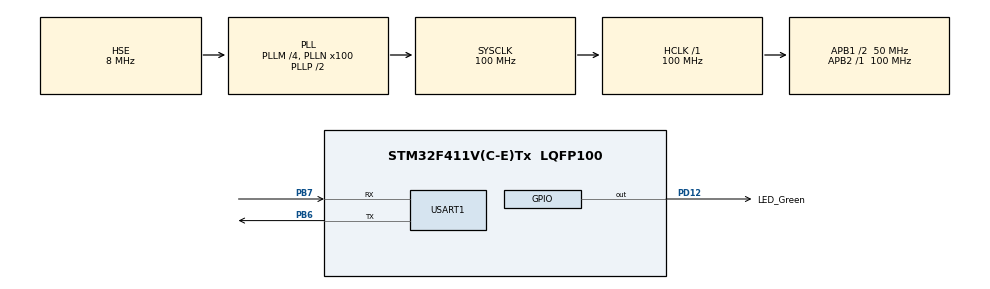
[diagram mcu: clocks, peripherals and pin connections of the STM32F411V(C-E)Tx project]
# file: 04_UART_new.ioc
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Dma.Request0=USART1_RX
Dma.Request1=USART1_TX
Dma.USART1_RX.0.Direction=DMA_PERIPH_TO_MEMORY
Dma.USART1_RX.0.FIFOMode=DMA_FIFOMODE_DISABLE
Dma.USART1_RX.0.Instance=DMA2_Stream2
Dma.USART1_RX.0.MemDataAlignment=DMA_MDATAALIGN_BYTE
Dma.USART1_RX.0.MemInc=DMA_MINC_ENABLE
Dma.USART1_RX.0.Mode=DMA_NORMAL
Dma.USART1_RX.0.PeriphDataAlignment=DMA_PDATAALIGN_BYTE
Dma.USART1_RX.0.PeriphInc=DMA_PINC_DISABLE
Dma.USART1_RX.0.Priority=DMA_PRIORITY_LOW
Dma.USART1_TX.1.Direction=DMA_MEMORY_TO_PERIPH
Dma.USART1_TX.1.FIFOMode=DMA_FIFOMODE_DISABLE
Dma.USART1_TX.1.Instance=DMA2_Stream7
Dma.USART1_TX.1.MemDataAlignment=DMA_MDATAALIGN_BYTE
Dma.USART1_TX.1.MemInc=DMA_MINC_ENABLE
Dma.USART1_TX.1.Mode=DMA_NORMAL
Dma.USART1_TX.1.PeriphDataAlignment=DMA_PDATAALIGN_BYTE
Dma.USART1_TX.1.PeriphInc=DMA_PINC_DISABLE
Dma.USART1_TX.1.Priority=DMA_PRIORITY_LOW
Mcu.Family=STM32F4
Mcu.Name=STM32F411V(C-E)Tx
Mcu.Package=LQFP100
NVIC.DMA2_Stream2_IRQn=true\:0\:0\:false\:false\:true
NVIC.DMA2_Stream7_IRQn=true\:0\:0\:false\:false\:true
NVIC.PriorityGroup=NVIC_PRIORITYGROUP_4
NVIC.TIM1_UP_TIM10_IRQn=true\:0\:0\:false\:false\:true
NVIC.USART1_IRQn=true\:0\:0\:false\:false\:true
PB6.Mode=Asynchronous
PB6.Signal=USART1_TX
PB7.Mode=Asynchronous
PB7.Signal=USART1_RX
PD12.GPIO_Label=LED_Green
PD12.Signal=GPIO_Output
PH0\ -\ OSC_IN.Mode=HSE-External-Oscillator
PH0\ -\ OSC_IN.Signal=RCC_OSC_IN
PH1\ -\ OSC_OUT.Mode=HSE-External-Oscillator
PH1\ -\ OSC_OUT.Signal=RCC_OSC_OUT
ProjectManager.HeapSize=0x200
ProjectManager.StackSize=0x400
ProjectManager.TargetToolchain=SW4STM32
RCC.48MHZClocksFreq_Value=50000000
RCC.AHBFreq_Value=100000000
RCC.APB1CLKDivider=RCC_HCLK_DIV2
RCC.APB1Freq_Value=50000000
RCC.APB1TimFreq_Value=100000000
RCC.APB2Freq_Value=100000000
RCC.APB2TimFreq_Value=100000000
RCC.CortexFreq_Value=100000000
RCC.HCLKFreq_Value=100000000
RCC.HSE_VALUE=8000000
RCC.HSI_VALUE=16000000
RCC.LSE_VALUE=32768
RCC.PLLM=4
RCC.PLLN=100
RCC.PLLSourceVirtual=RCC_PLLSOURCE_HSE
RCC.SYSCLKFreq_VALUE=100000000
RCC.SYSCLKSource=RCC_SYSCLKSOURCE_PLLCLK
RCC.VCOOutputFreq_Value=200000000
TIM10.Period=9999
TIM10.Prescaler=9999
USART1.VirtualMode=VM_ASYNC
VP_TIM10_VS_ClockSourceINT.Mode=Enable_Timer
board=04_UART_new

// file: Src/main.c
/**
  ******************************************************************************
  * File Name          : main.c
  * Description        : Main program body
  ******************************************************************************
  *
  * COPYRIGHT(c) 2017 STMicroelectronics
  *
  * Redistribution and use in source and binary forms, with or without modification,
  * are permitted provided that the following conditions are met:
  *   1. Redistributions of source code must retain the above copyright notice,
  *      this list of conditions and the following disclaimer.
  *   2. Redistributions in binary form must reproduce the above copyright notice,
  *      this list of conditions and the following disclaimer in the documentation
  *      and/or other materials provided with the distribution.
  *   3. Neither the name of STMicroelectronics nor the names of its contributors
  *      may be used to endorse or promote products derived from this software
  *      without specific prior written permission.
  *
  * THIS SOFTWARE IS PROVIDED BY THE COPYRIGHT HOLDERS AND CONTRIBUTORS "AS IS"
  * AND ANY EXPRESS OR IMPLIED WARRANTIES, INCLUDING, BUT NOT LIMITED TO, THE
  * IMPLIED WARRANTIES OF MERCHANTABILITY AND FITNESS FOR A PARTICULAR PURPOSE ARE
  * DISCLAIMED. IN NO EVENT SHALL THE COPYRIGHT HOLDER OR CONTRIBUTORS BE LIABLE
  * FOR ANY DIRECT, INDIRECT, INCIDENTAL, SPECIAL, EXEMPLARY, OR CONSEQUENTIAL
  * DAMAGES (INCLUDING, BUT NOT LIMITED TO, PROCUREMENT OF SUBSTITUTE GOODS OR
  * SERVICES; LOSS OF USE, DATA, OR PROFITS; OR BUSINESS INTERRUPTION) HOWEVER
  * CAUSED AND ON ANY THEORY OF LIABILITY, WHETHER IN CONTRACT, STRICT LIABILITY,
  * OR TORT (INCLUDING NEGLIGENCE OR OTHERWISE) ARISING IN ANY WAY OUT OF THE USE
  * OF THIS SOFTWARE, EVEN IF ADVISED OF THE POSSIBILITY OF SUCH DAMAGE.
  *
  ******************************************************************************
  */
#include "main.h"
#include "stm32f4xx_hal.h"

TIM_HandleTypeDef htim10;

UART_HandleTypeDef huart1;
DMA_HandleTypeDef hdma_usart1_rx;
DMA_HandleTypeDef hdma_usart1_tx;

/* USER CODE BEGIN PV */
/* Private variables ---------------------------------------------------------*/
uint8_t Received[10];
/* USER CODE END PV */

void SystemClock_Config(void);
void Error_Handler(void);
static void MX_GPIO_Init(void);
static void MX_DMA_Init(void);
static void MX_TIM10_Init(void);
static void MX_USART1_UART_Init(void);

/* USER CODE BEGIN PFP */
/* Private function prototypes -----------------------------------------------*/
//void HAL_TIM_PeriodElapsedCallback(TIM_HandleTypeDef *htim) {
//	if (htim->Instance == TIM10) {
//		static uint16_t cnt = 0; // Licznik wyslanych wiadomosci
//		uint8_t data[50]; // Tablica przechowujaca wysylana wiadomosc.
//		uint16_t size = 0; // Rozmiar wysylanej wiadomosci ++cnt; // Zwiekszenie licznika wyslanych wiadomosci.
//
//		++cnt; // Zwiekszenie licznika wyslanych wiadomosci.
//		size = sprintf((char*)data, "Liczba wyslanych wiadomosci: %d.\n\r", cnt); // Stworzenie wiadomosci do wyslania oraz przypisanie ilosci wysylanych znakow do zmiennej size.
//		HAL_UART_Transmit_IT(&huart1, data, size); // Rozpoczecie nadawania danych z wykorzystaniem przerwan
//		HAL_GPIO_TogglePin(LED_Green_GPIO_Port, LED_Green_Pin); // Zmiana stanu pinu na diodzie LED
//	}
//}
void HAL_UART_RxCpltCallback(UART_HandleTypeDef *huart) {

	static uint8_t Data[40]; // Tablica przechowujaca wysylana wiadomosc. Musi byc s
//	uint16_t size = 0; // Rozmiar wysylanej wiadomosci

	// Odebrany znak zostaje przekonwertowany na liczbe calkowita i sprawdzony
	// instrukcja warunkowa
//	switch (Received) {
//
//	case 'a': // Jezeli odebrany zostanie znak 0
//		size = sprintf((char*)Data, "STOP\n\r");
////		Data = "STOP\n\r"; size = 8;
//		HAL_GPIO_WritePin(LED_Green_GPIO_Port, LED_Green_Pin, GPIO_PIN_RESET);
//		break;
//
//	case 'b': // Jezeli odebrany zostanie znak 1
//		size = sprintf((char*)Data, "START\n\r");
////		Data = "START\n\r"; size = 9;
//		HAL_GPIO_WritePin(LED_Green_GPIO_Port, LED_Green_Pin, GPIO_PIN_SET);
//		break;
//
//	default: // Jezeli odebrano nieobslugiwany znak
//		size = sprintf((char*)Data, "Odebrano nieznany znak: %c\n\r", Received);
//		break;
//	}
	sprintf((char*)Data, "Odebrana wiadomosc: %s\n\r", Received);

	HAL_UART_Transmit_DMA(&huart1, Data, 40); // Rozpoczecie nadawania danych z wykorzystaniem DMA
	HAL_UART_Receive_DMA(&huart1, Received, 10); // Ponowne w³¹czenie nas³uchiwania
	HAL_GPIO_TogglePin(LED_Green_GPIO_Port, LED_Green_Pin);
}
/* USER CODE END PFP */

int main(void)
{

  /* MCU Configuration----------------------------------------------------------*/

  /* Reset of all peripherals, Initializes the Flash interface and the Systick. */
  HAL_Init();

  /* Configure the system clock */
  SystemClock_Config();

  /* Initialize all configured peripherals */
  MX_GPIO_Init();
  MX_DMA_Init();
  MX_TIM10_Init();
  MX_USART1_UART_Init();

  /* USER CODE BEGIN 2 */
//	HAL_TIM_Base_Start_IT(&htim10);
	HAL_UART_Receive_DMA(&huart1, Received, 10);
  /* USER CODE END 2 */

  /* Infinite loop */
	while (1) {

	}

}

/** System Clock Configuration
*/
void SystemClock_Config(void)
{

  RCC_OscInitTypeDef RCC_OscInitStruct;
  RCC_ClkInitTypeDef RCC_ClkInitStruct;

    /**Configure the main internal regulator output voltage
    */
  __HAL_RCC_PWR_CLK_ENABLE();

  __HAL_PWR_VOLTAGESCALING_CONFIG(PWR_REGULATOR_VOLTAGE_SCALE1);

    /**Initializes the CPU, AHB and APB busses clocks
    */
  RCC_OscInitStruct.OscillatorType = RCC_OSCILLATORTYPE_HSE;
  RCC_OscInitStruct.HSEState = RCC_HSE_ON;
  RCC_OscInitStruct.PLL.PLLState = RCC_PLL_ON;
  RCC_OscInitStruct.PLL.PLLSource = RCC_PLLSOURCE_HSE;
  RCC_OscInitStruct.PLL.PLLM = 4;
  RCC_OscInitStruct.PLL.PLLN = 100;
  RCC_OscInitStruct.PLL.PLLP = RCC_PLLP_DIV2;
  RCC_OscInitStruct.PLL.PLLQ = 4;
  if (HAL_RCC_OscConfig(&RCC_OscInitStruct) != HAL_OK)
  {
    Error_Handler();
  }

    /**Initializes the CPU, AHB and APB busses clocks
    */
  RCC_ClkInitStruct.ClockType = RCC_CLOCKTYPE_HCLK|RCC_CLOCKTYPE_SYSCLK
                              |RCC_CLOCKTYPE_PCLK1|RCC_CLOCKTYPE_PCLK2;
  RCC_ClkInitStruct.SYSCLKSource = RCC_SYSCLKSOURCE_PLLCLK;
  RCC_ClkInitStruct.AHBCLKDivider = RCC_SYSCLK_DIV1;
  RCC_ClkInitStruct.APB1CLKDivider = RCC_HCLK_DIV2;
  RCC_ClkInitStruct.APB2CLKDivider = RCC_HCLK_DIV1;

  if (HAL_RCC_ClockConfig(&RCC_ClkInitStruct, FLASH_LATENCY_3) != HAL_OK)
  {
    Error_Handler();
  }

    /**Configure the Systick interrupt time
    */
  HAL_SYSTICK_Config(HAL_RCC_GetHCLKFreq()/1000);

    /**Configure the Systick
    */
  HAL_SYSTICK_CLKSourceConfig(SYSTICK_CLKSOURCE_HCLK);

  /* SysTick_IRQn interrupt configuration */
  HAL_NVIC_SetPriority(SysTick_IRQn, 0, 0);
}

/* TIM10 init function */
static void MX_TIM10_Init(void)
{

  htim10.Instance = TIM10;
  htim10.Init.Prescaler = 9999;
  htim10.Init.CounterMode = TIM_COUNTERMODE_UP;
  htim10.Init.Period = 9999;
  htim10.Init.ClockDivision = TIM_CLOCKDIVISION_DIV1;
  if (HAL_TIM_Base_Init(&htim10) != HAL_OK)
  {
    Error_Handler();
  }

}

/* USART1 init function */
static void MX_USART1_UART_Init(void)
{

  huart1.Instance = USART1;
  huart1.Init.BaudRate = 115200;
  huart1.Init.WordLength = UART_WORDLENGTH_8B;
  huart1.Init.StopBits = UART_STOPBITS_1;
  huart1.Init.Parity = UART_PARITY_NONE;
  huart1.Init.Mode = UART_MODE_TX_RX;
  huart1.Init.HwFlowCtl = UART_HWCONTROL_NONE;
  huart1.Init.OverSampling = UART_OVERSAMPLING_16;
  if (HAL_UART_Init(&huart1) != HAL_OK)
  {
    Error_Handler();
  }

}

static void MX_DMA_Init(void)
{
  /* DMA controller clock enable */
  __HAL_RCC_DMA2_CLK_ENABLE();

  /* DMA interrupt init */
  /* DMA2_Stream2_IRQn interrupt configuration */
  HAL_NVIC_SetPriority(DMA2_Stream2_IRQn, 0, 0);
  HAL_NVIC_EnableIRQ(DMA2_Stream2_IRQn);
  /* DMA2_Stream7_IRQn interrupt configuration */
  HAL_NVIC_SetPriority(DMA2_Stream7_IRQn, 0, 0);
  HAL_NVIC_EnableIRQ(DMA2_Stream7_IRQn);

}

/** Configure pins as
        * Analog
        * Input
        * Output
        * EVENT_OUT
        * EXTI
*/
static void MX_GPIO_Init(void)
{

  GPIO_InitTypeDef GPIO_InitStruct;

  /* GPIO Ports Clock Enable */
  __HAL_RCC_GPIOH_CLK_ENABLE();
  __HAL_RCC_GPIOD_CLK_ENABLE();
  __HAL_RCC_GPIOB_CLK_ENABLE();

  /*Configure GPIO pin Output Level */
  HAL_GPIO_WritePin(LED_Green_GPIO_Port, LED_Green_Pin, GPIO_PIN_RESET);

  /*Configure GPIO pin : LED_Green_Pin */
  GPIO_InitStruct.Pin = LED_Green_Pin;
  GPIO_InitStruct.Mode = GPIO_MODE_OUTPUT_PP;
  GPIO_InitStruct.Pull = GPIO_NOPULL;
  GPIO_InitStruct.Speed = GPIO_SPEED_FREQ_LOW;
  HAL_GPIO_Init(LED_Green_GPIO_Port, &GPIO_InitStruct);

}

void Error_Handler(void)
{
	while (1) {
	}
}

/************************ (C) COPYRIGHT STMicroelectronics *****END OF FILE****/
